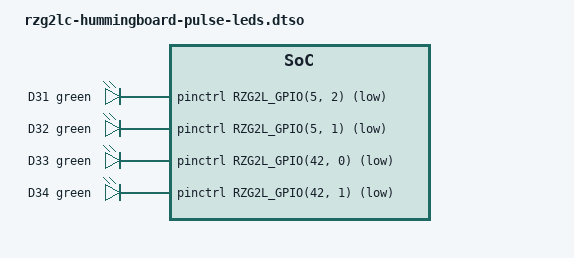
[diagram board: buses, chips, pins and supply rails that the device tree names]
// SPDX-License-Identifier: (GPL-2.0-only OR BSD-2-Clause)
/*
 * Overlay for SolidRun RZ/G2LC HummingBoard Pulse
 * enabling LEDs D31-34 in exchange for on-SoM Bluetooth.
 *
 * Copyright 2025 Josua Mayer <josua@solid-run.com>
 */

/dts-v1/;
/plugin/;

#include <dt-bindings/gpio/gpio.h>
#include <dt-bindings/leds/common.h>
#include <dt-bindings/pinctrl/rzg2l-pinctrl.h>

&leds {
	led-1 {
		label = "D31";
		color = <LED_COLOR_ID_GREEN>;
		gpios = <&pinctrl RZG2L_GPIO(5, 2) GPIO_ACTIVE_LOW>;
		default-state = "on";
	};

	led-2 {
		label = "D32";
		color = <LED_COLOR_ID_GREEN>;
		gpios = <&pinctrl RZG2L_GPIO(5, 1) GPIO_ACTIVE_LOW>;
		default-state = "on";
	};

	led-3 {
		label = "D33";
		color = <LED_COLOR_ID_GREEN>;
		gpios = <&pinctrl RZG2L_GPIO(42, 0) GPIO_ACTIVE_LOW>;
		default-state = "on";
	};

	led-4 {
		label = "D34";
		color = <LED_COLOR_ID_GREEN>;
		gpios = <&pinctrl RZG2L_GPIO(42, 1) GPIO_ACTIVE_LOW>;
		default-state = "on";
	};
};

&scif2 {
	status = "disabled";
};
